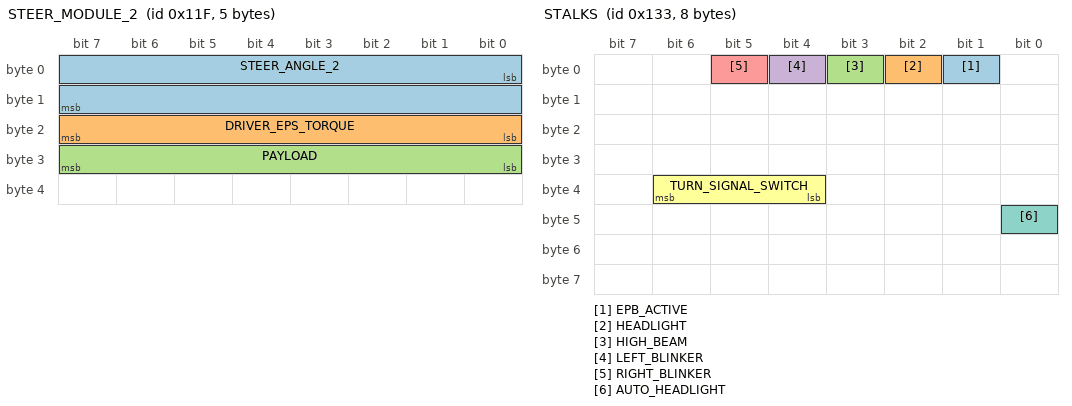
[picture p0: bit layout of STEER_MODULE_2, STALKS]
BO_ 287 STEER_MODULE_2: 5 XXX
 SG_ STEER_ANGLE_2 : 0|16@1- (0.1,0) [0|65535] "" XXX
 SG_ DRIVER_EPS_TORQUE : 16|8@1+ (1,0) [0|255] "" XXX
 SG_ PAYLOAD : 24|8@1+ (1,0) [0|255] "" XXX

BO_ 307 STALKS: 8 XXX
 SG_ EPB_ACTIVE : 1|1@1+ (1,0) [0|1] "" XXX
 SG_ HEADLIGHT : 2|1@1+ (1,0) [0|1] "" XXX
 SG_ HIGH_BEAM : 3|1@1+ (1,0) [0|1] "" XXX
 SG_ LEFT_BLINKER : 4|1@0+ (1,0) [0|1] "" XXX
 SG_ RIGHT_BLINKER : 5|1@0+ (1,0) [0|1] "" XXX
 SG_ TURN_SIGNAL_SWITCH : 36|3@1+ (1,0) [0|7] "" XXX
 SG_ AUTO_HEADLIGHT : 40|1@0+ (1,0) [0|1] "" XXX

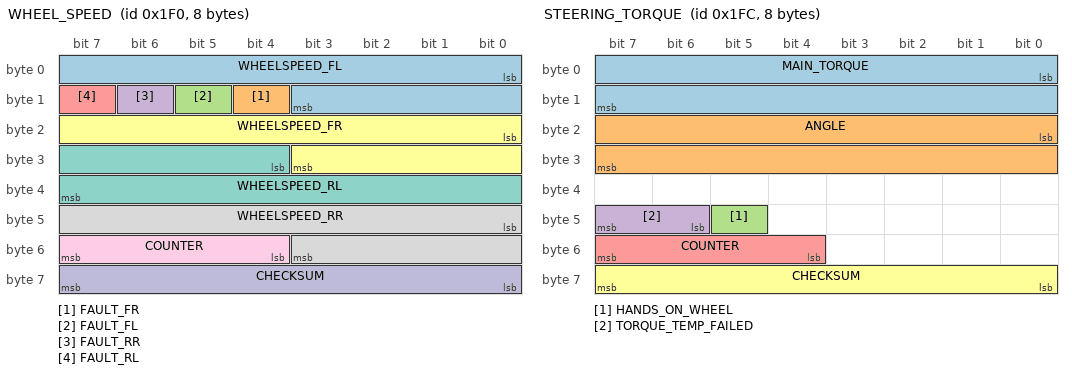
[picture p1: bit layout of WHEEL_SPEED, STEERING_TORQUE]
BO_ 496 WHEEL_SPEED: 8 XXX
 SG_ WHEELSPEED_FL : 0|12@1+ (0.1,0) [0|281.4625] "km/h" XXX
 SG_ FAULT_FR : 12|1@1+ (1,0) [0|1] "" XXX
 SG_ FAULT_FL : 13|1@1+ (1,0) [0|1] "" XXX
 SG_ FAULT_RR : 14|1@1+ (1,0) [0|1] "" XXX
 SG_ FAULT_RL : 15|1@1+ (1,0) [0|1] "" XXX
 SG_ WHEELSPEED_FR : 16|12@1+ (0.1,0) [0|281.4625] "km/h" XXX
 SG_ WHEELSPEED_RL : 28|12@1+ (0.1,0) [0|281.4625] "km/h" XXX
 SG_ WHEELSPEED_RR : 40|12@1+ (0.1,0) [0|281.4625] "km/h" XXX
 SG_ COUNTER : 55|4@0+ (1,0) [0|15] "" XXX
 SG_ CHECKSUM : 63|8@0+ (1,0) [0|255] "" XXX

BO_ 508 STEERING_TORQUE: 8 XXX
 SG_ MAIN_TORQUE : 0|16@1- (0.1,0) [0|65535] "" XXX
 SG_ ANGLE : 16|16@1- (0.1,0) [0|255] "" XXX
 SG_ HANDS_ON_WHEEL : 45|1@1+ (1,0) [0|255] "" XXX
 SG_ TORQUE_TEMP_FAILED : 46|2@1+ (1,0) [0|3] "" XXX
 SG_ COUNTER : 55|4@0+ (1,0) [0|15] "" XXX
 SG_ CHECKSUM : 63|8@0+ (1,0) [0|255] "" XXX

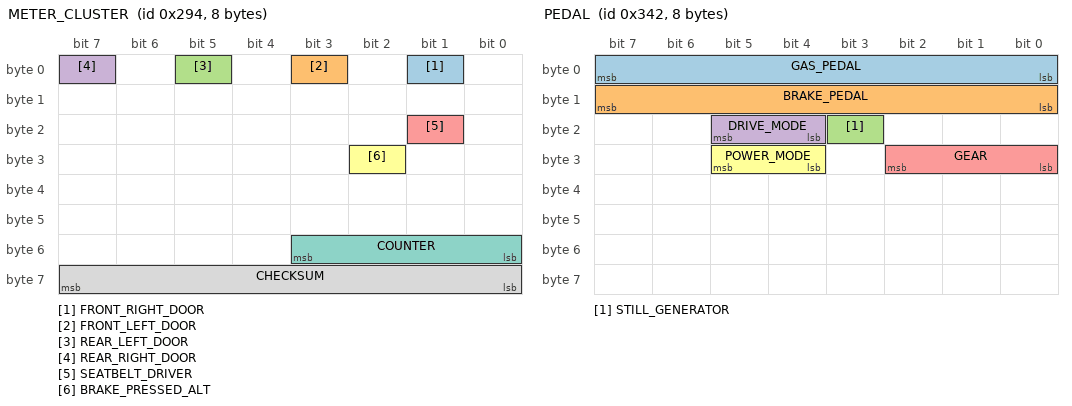
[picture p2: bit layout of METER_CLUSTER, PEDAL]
BO_ 660 METER_CLUSTER: 8 XXX
 SG_ FRONT_RIGHT_DOOR : 1|1@1+ (1,0) [0|511] "" XXX
 SG_ FRONT_LEFT_DOOR : 3|1@0+ (1,0) [0|1] "" XXX
 SG_ REAR_LEFT_DOOR : 5|1@1+ (1,0) [0|511] "" XXX
 SG_ REAR_RIGHT_DOOR : 7|1@0+ (1,0) [0|1] "" XXX
 SG_ SEATBELT_DRIVER : 17|1@0+ (1,0) [0|1] "" XXX
 SG_ BRAKE_PRESSED_ALT : 26|1@1+ (1,0) [0|1] "" XXX
 SG_ COUNTER : 48|4@1+ (1,0) [0|255] "" XXX
 SG_ CHECKSUM : 56|8@1+ (1,0) [0|255] "" XXX

BO_ 834 PEDAL: 8 XXX
 SG_ GAS_PEDAL : 0|8@1+ (0.01,0) [0|2.55] "" XXX
 SG_ BRAKE_PEDAL : 8|8@1+ (0.01,0) [0|2.55] "" XXX
 SG_ STILL_GENERATOR : 19|1@1+ (1,0) [0|1] "" XXX
 SG_ DRIVE_MODE : 20|2@1+ (1,0) [0|255] "" XXX
 SG_ GEAR : 26|3@0+ (1,0) [0|7] "" XXX
 SG_ POWER_MODE : 28|2@1+ (1,0) [0|1] "" XXX

BO_ 1048 BSM: 8 XXX
 SG_ LEFT_APPROACH : 23|1@0+ (1,0) [0|1] "" XXX
 SG_ RIGHT_APPROACH : 17|1@0+ (1,0) [0|1] "" XXX

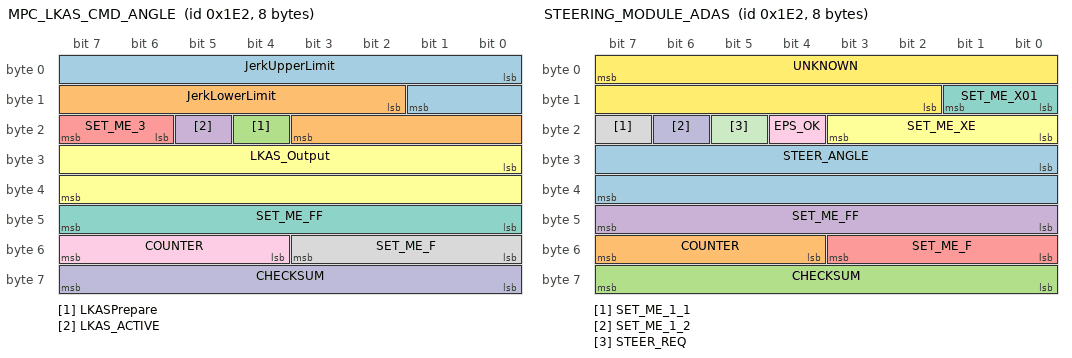
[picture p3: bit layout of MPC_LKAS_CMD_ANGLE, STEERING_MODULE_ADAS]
BO_ 482 MPC_LKAS_CMD_ANGLE: 8 XXX
 SG_ JerkUpperLimit : 0|10@1- (1,0) [0|65535] "" XXX
 SG_ JerkLowerLimit : 10|10@1- (1,0) [0|15] "" XXX
 SG_ LKASPrepare : 20|1@0+ (1,0) [0|1] "" XXX
 SG_ LKAS_ACTIVE : 21|1@0+ (1,0) [0|1] "" XXX
 SG_ SET_ME_3 : 22|2@1+ (1,0) [0|1] "" XXX
 SG_ LKAS_Output : 24|16@1- (0.1,0) [0|255] "" XXX
 SG_ SET_ME_FF : 47|8@0+ (1,0) [0|255] "" XXX
 SG_ SET_ME_F : 48|4@1+ (1,0) [0|15] "" XXX
 SG_ COUNTER : 52|4@1+ (1,0) [0|15] "" XXX
 SG_ CHECKSUM : 56|8@1+ (1,0) [0|255] "" XXX

BO_ 482 STEERING_MODULE_ADAS: 8 XXX
 SG_ STEER_ANGLE : 24|16@1- (0.1,0) [0|255] "" XXX
 SG_ COUNTER : 55|4@0+ (1,0) [0|15] "" XXX
 SG_ CHECKSUM : 63|8@0+ (1,0) [0|255] "" XXX
 SG_ SET_ME_FF : 47|8@0+ (1,0) [0|255] "" XXX
 SG_ SET_ME_F : 48|4@1+ (1,0) [0|15] "" XXX
 SG_ SET_ME_XE : 16|4@1+ (1,0) [0|15] "" XXX
 SG_ SET_ME_X01 : 8|2@1+ (1,0) [0|3] "" XXX
 SG_ SET_ME_1_1 : 23|1@0+ (1,0) [0|1] "" XXX
 SG_ EPS_OK : 20|1@0+ (1,0) [0|1] "" XXX
 SG_ SET_ME_1_2 : 22|1@0+ (1,0) [0|3] "" XXX
 SG_ STEER_REQ : 21|1@0+ (1,0) [0|1] "" XXX
 SG_ UNKNOWN : 7|14@0- (1,0) [0|65535] "" XXX

VAL_ 307 TURN_SIGNAL_SWITCH 0 "Invalid" 1 "OFFGear" 2 "LeftSteeringShortLift" 3 "LeftSteeringLongLift" 4 "RightSteeringShortLift" 5 "RightSteeringLongLift" 7 "Unavaliable";
VAL_ 834 GEAR 4 "D" 2 "R" 1 "P";
